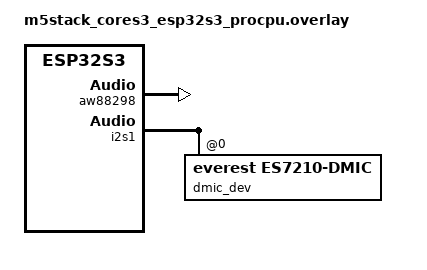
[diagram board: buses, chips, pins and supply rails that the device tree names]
/*
 * Copyright (c) 2025 TOKITA Hiroshi
 *
 * SPDX-License-Identifier: Apache-2.0
 */

/ {
        aliases {
                i2s-codec-tx = &i2s1;
        };
};

audio_codec: &aw88298 {
        status = "okay";
};

&i2s1 {
        status = "okay";

        dmic_dev: es7210_dmic@0 {
                compatible = "everest,es7210-dmic";
                reg = <0>;
                status = "okay";
                codec = <&es7210>;
        };
};

&dma {
        status = "okay";
};
